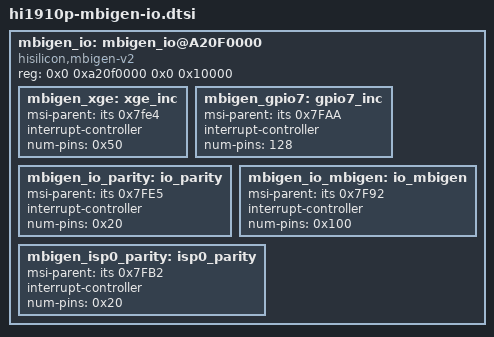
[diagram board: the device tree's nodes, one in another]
/**
* dts file for Hisilicon Ascend Dxxx Development Board
*
* Copyright (C) 2020 Hisilicon Ltd.
*
* This program is free software; you can redistribute it and/or modify
* it under the terms of the GNU General Public License version 2 as
* publishhed by the Free Software Foundation.
*
* Owner：OS
* Author:  c00283067
* Create: Tue Apr 21 20:07:41 EDT 2020
*/
    mbigen_io: mbigen_io@A20F0000 {
        compatible = "hisilicon,mbigen-v2";
        reg = <0x0 0xa20f0000 0x0 0x10000>;
        mbigen_xge: xge_inc {
            msi-parent = <&its 0x7fe4>;
            interrupt-controller;
            #interrupt-cells = <0x2>;
            num-pins = <0x50>;
        };

        mbigen_gpio7: gpio7_inc {
            msi-parent = <&its 0x7FAA>;
            interrupt-controller;
            #interrupt-cells = <0x2>;
            num-pins = <128>;
        };
        mbigen_io_parity: io_parity {
            msi-parent = <&its 0x7FE5>;
            interrupt-controller;
            #interrupt-cells = <0x2>;
            num-pins = <0x20>;
        };
        mbigen_io_mbigen: io_mbigen {
            msi-parent = <&its 0x7F92>;
            interrupt-controller;
            #interrupt-cells = <0x2>;
            num-pins = <0x100>;
        };
        mbigen_isp0_parity: isp0_parity {
            msi-parent = <&its 0x7FB2>;
            interrupt-controller;
            #interrupt-cells = <0x2>;
            num-pins = <0x20>;
        };
    };
